# CTRL_MODULE_WKUP_PAD register map
Vendor: Texas Instruments
Peripheral module from a debugger description file (folder omap5430_ES2_PUBLIC).
Registers are 32-bit, access per field, reset 0x0 unless marked. A register's access mark holds for its fields unless they carry their own. Offsets are as the file gives them; lines under a group give offsets from that group; [hi:lo] are bit positions; {n}, {i} and the like mark numbered series; 'fields as' and 'values as' point back to an identical list; <NAME> marks a mode.

## CTRL_MODULE_WKUP_PAD
0x00 CONTROL_WKUP_PAD_REVISION ro reset not defined — Control module revision identifier Access conditions. Read: unrestricted, Write: unrestricted
  [31:0] REVISON — IP Revision enum=hl_scheme . enum=legacy_scheme .
0x04 CONTROL_WKUP_PAD_HWINFO ro — Information about the IP module hardware configuration i.e. typically the module HDL generics (if any). Access conditions. Read: unrestricted, Write: unrestricted
  [31:0] IP_HWINFO — IP-module dependent
0x10 CONTROL_WKUP_PAD_SYSCONFIG reset 0x8 — Access conditions. Read: unrestricted, Write: unrestricted
  [3:2] IP_SYSCONFIG_IDLEMODE rw — RESERVED (not used).
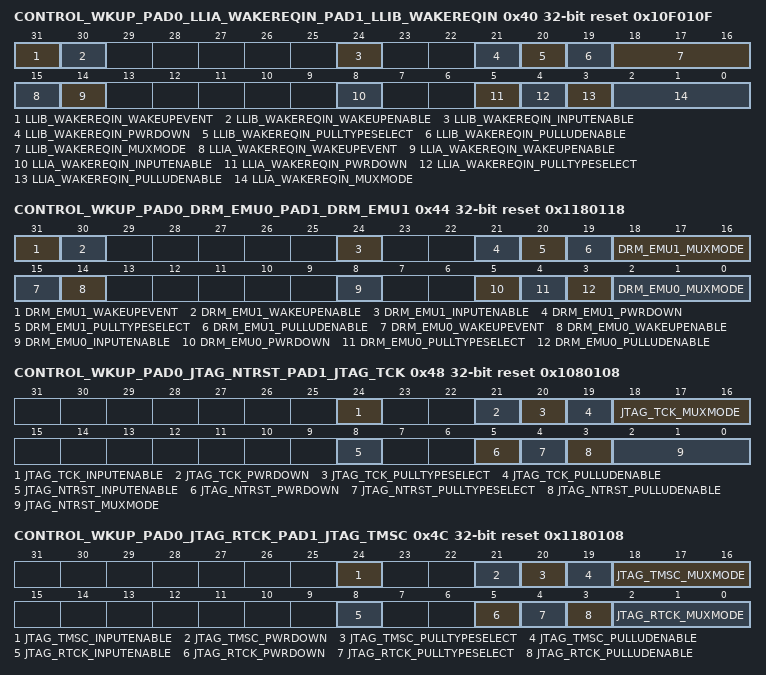
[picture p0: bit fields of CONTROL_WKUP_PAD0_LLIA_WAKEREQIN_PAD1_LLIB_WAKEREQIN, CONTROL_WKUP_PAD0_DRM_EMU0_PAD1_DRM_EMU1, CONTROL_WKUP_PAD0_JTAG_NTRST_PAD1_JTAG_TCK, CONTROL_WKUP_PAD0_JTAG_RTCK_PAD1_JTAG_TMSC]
0x40 CONTROL_WKUP_PAD0_LLIA_WAKEREQIN_PAD1_LLIB_WAKEREQIN reset 0x10F010F — Register control for Pads llia_wakereqin and llib_wakereqin Access conditions. Read: unrestricted, Write: unrestricted
  [31] LLIB_WAKEREQIN_WAKEUPEVENT ro — Pad_x wake-up event status latched in the IO
    1=WakeUp (A wake-up event occurred); 0=No wake-up event occurred
  [30] LLIB_WAKEREQIN_WAKEUPENABLE rw — Input pad wake-up enable
    0=DetectLow (wake-up detection is disabled); 1=DetectLowHigh (wake-up detection is enabled)
  [24] LLIB_WAKEREQIN_INPUTENABLE rw — Input enable value for pad llib_wakereqin
    0=InputBufferDisabled (Input buffer of IO cell is disabled); 1=InputBufferEnabled (Input buffer of IO cell is enabled)
  [21] LLIB_WAKEREQIN_PWRDOWN rw — Power Down setting for pad llib_wakereqin
    0=PwrDownDisabled (IO cell power is ON); 1=PwrDownEnabled (IO cell power is OFF)
  [20] LLIB_WAKEREQIN_PULLTYPESELECT rw — Pull-Up/Down selection for pad llib_wakereqin
    0=Pull-Down selected; 1=Pull-Up selected
  [19] LLIB_WAKEREQIN_PULLUDENABLE rw — Pull-Up/Down enable for pad llib_wakereqin
    0=PullDisabled (Pull-Up/Down disabled); 1=PullEnabled (Pull-Up/Down enabled)
  [18:16] LLIB_WAKEREQIN_MUXMODE rw — Functional multiplexing selection for pad llib_wakereqin
    0=SEL_LLIB_WAKEREQIN (Select llib_wakereqin); 1=SEL_SYS_C2C_PWKUP (Reserved); 6=SEL_GPIO1_WK15 (Select gpio1_wk15); 7=SEL_SAFE_MODE_WAKEUP0 (Select safe_mode_wakeup0); 5=SEL_HW_WKDBG13 (Select hw_wkdbg13)
  [15] LLIA_WAKEREQIN_WAKEUPEVENT ro — Pad_x wake-up event status latched in the IO
    values as LLIB_WAKEREQIN_WAKEUPEVENT
  [14] LLIA_WAKEREQIN_WAKEUPENABLE rw — Input pad wake-up enable
    values as LLIB_WAKEREQIN_WAKEUPENABLE
  [8] LLIA_WAKEREQIN_INPUTENABLE rw — Input enable value for pad llia_wakereqin
    values as LLIB_WAKEREQIN_INPUTENABLE
  [5] LLIA_WAKEREQIN_PWRDOWN rw — Power Down setting for pad llia_wakereqin
    values as LLIB_WAKEREQIN_PWRDOWN
  [4] LLIA_WAKEREQIN_PULLTYPESELECT rw — Pull-Up/Down selection for pad llia_wakereqin
    0=Pull-Down selected; 1=Pull-Up selected
  [3] LLIA_WAKEREQIN_PULLUDENABLE rw — Pull-Up/Down enable for pad llia_wakereqin
    values as LLIB_WAKEREQIN_PULLUDENABLE
  [2:0] LLIA_WAKEREQIN_MUXMODE rw — Functional multiplexing selection for pad llia_wakereqin
    0=SEL_LLIA_WAKEREQIN (Select llia_wakereqin); 1=SEL_C2C_WAKEREQIN (Reserved); 6=SEL_GPIO1_WK14 (Select gpio1_wk14); 7=SEL_SAFE_MODE_WAKEUP1 (Select safe_mode_wakeup1); 5=SEL_HW_WKDBG14 (Select hw_wkdbg14)
0x44 CONTROL_WKUP_PAD0_DRM_EMU0_PAD1_DRM_EMU1 reset 0x1180118 — Register control for Pads drm_emu0 and drm_emu1 Access conditions. Read: unrestricted, Write: unrestricted
  [31] DRM_EMU1_WAKEUPEVENT ro — Pad_x wake-up event status latched in the IO
    values as CONTROL_WKUP_PAD0_LLIA_WAKEREQIN_PAD1_LLIB_WAKEREQIN.LLIB_WAKEREQIN_WAKEUPEVENT
  [30] DRM_EMU1_WAKEUPENABLE rw — Input pad wake-up enable
    values as CONTROL_WKUP_PAD0_LLIA_WAKEREQIN_PAD1_LLIB_WAKEREQIN.LLIB_WAKEREQIN_WAKEUPENABLE
  [24] DRM_EMU1_INPUTENABLE rw — Input enable value for pad drm_emu1
    values as CONTROL_WKUP_PAD0_LLIA_WAKEREQIN_PAD1_LLIB_WAKEREQIN.LLIB_WAKEREQIN_INPUTENABLE
  [21] DRM_EMU1_PWRDOWN rw — Power Down setting for pad drm_emu1
    values as CONTROL_WKUP_PAD0_LLIA_WAKEREQIN_PAD1_LLIB_WAKEREQIN.LLIB_WAKEREQIN_PWRDOWN
  [20] DRM_EMU1_PULLTYPESELECT rw — Pull-Up/Down selection for pad drm_emu1
    0=Pull-Down selected; 1=Pull-Up selected
  [19] DRM_EMU1_PULLUDENABLE rw — Pull-Up/Down enable for pad drm_emu1
    values as CONTROL_WKUP_PAD0_LLIA_WAKEREQIN_PAD1_LLIB_WAKEREQIN.LLIB_WAKEREQIN_PULLUDENABLE
  [18:16] DRM_EMU1_MUXMODE rw — Functional multiplexing selection for pad drm_emu1
    0=SEL_DRM_EMU1 (Select drm_emu1); 6=SEL_GPIO1_WK7 (Select gpio1_wk7); 7=SEL_SAFE_MODE_WAKEUP3 (Select safe_mode_wakeup3); 5=SEL_HW_WKDBG7 (Select hw_wkdbg7)
  [15] DRM_EMU0_WAKEUPEVENT ro — Pad_x wake-up event status latched in the IO
    values as CONTROL_WKUP_PAD0_LLIA_WAKEREQIN_PAD1_LLIB_WAKEREQIN.LLIB_WAKEREQIN_WAKEUPEVENT
  [14] DRM_EMU0_WAKEUPENABLE rw — Input pad wake-up enable
    values as CONTROL_WKUP_PAD0_LLIA_WAKEREQIN_PAD1_LLIB_WAKEREQIN.LLIB_WAKEREQIN_WAKEUPENABLE
  [8] DRM_EMU0_INPUTENABLE rw — Input enable value for pad drm_emu0
    values as CONTROL_WKUP_PAD0_LLIA_WAKEREQIN_PAD1_LLIB_WAKEREQIN.LLIB_WAKEREQIN_INPUTENABLE
  [5] DRM_EMU0_PWRDOWN rw — Power Down setting for pad drm_emu0
    values as CONTROL_WKUP_PAD0_LLIA_WAKEREQIN_PAD1_LLIB_WAKEREQIN.LLIB_WAKEREQIN_PWRDOWN
  [4] DRM_EMU0_PULLTYPESELECT rw — Pull-Up/Down selection for pad drm_emu0
    0=Pull-Down selected; 1=Pull-Up selected
  [3] DRM_EMU0_PULLUDENABLE rw — Pull-Up/Down enable for pad drm_emu0
    values as CONTROL_WKUP_PAD0_LLIA_WAKEREQIN_PAD1_LLIB_WAKEREQIN.LLIB_WAKEREQIN_PULLUDENABLE
  [2:0] DRM_EMU0_MUXMODE rw — Functional multiplexing selection for pad drm_emu0
    0=SEL_DRM_EMU0 (Select drm_emu0); 6=SEL_GPIO1_WK6 (Select gpio1_wk6); 7=SEL_SAFE_MODE_WAKEUP2 (Select safe_mode_wakeup2); 5=SEL_HW_WKDBG6 (Select hw_wkdbg6)
0x48 CONTROL_WKUP_PAD0_JTAG_NTRST_PAD1_JTAG_TCK reset 0x1080108 — Register control for Pads jtag_ntrst and jtag_tck Access conditions. Read: unrestricted, Write: unrestricted
  [24] JTAG_TCK_INPUTENABLE rw — Input enable value for pad jtag_tck
    values as CONTROL_WKUP_PAD0_LLIA_WAKEREQIN_PAD1_LLIB_WAKEREQIN.LLIB_WAKEREQIN_INPUTENABLE
  [21] JTAG_TCK_PWRDOWN rw — Power Down setting for pad jtag_tck
    values as CONTROL_WKUP_PAD0_LLIA_WAKEREQIN_PAD1_LLIB_WAKEREQIN.LLIB_WAKEREQIN_PWRDOWN
  [20] JTAG_TCK_PULLTYPESELECT rw — Pull-Up/Down selection for pad jtag_tck
    0=Pull-Down selected; 1=Pull-Up selected
  [19] JTAG_TCK_PULLUDENABLE rw — Pull-Up/Down enable for pad jtag_tck
    values as CONTROL_WKUP_PAD0_LLIA_WAKEREQIN_PAD1_LLIB_WAKEREQIN.LLIB_WAKEREQIN_PULLUDENABLE
  [18:16] JTAG_TCK_MUXMODE rw — Functional multiplexing selection for pad jtag_tck
    0=SEL_JTAG_TCK (Select jtag_tck); 7=SEL_SAFE_MODE_WAKEUP5 (Select safe_mode_wakeup5)
  [8] JTAG_NTRST_INPUTENABLE rw — Input enable value for pad jtag_ntrst
    values as CONTROL_WKUP_PAD0_LLIA_WAKEREQIN_PAD1_LLIB_WAKEREQIN.LLIB_WAKEREQIN_INPUTENABLE
  [5] JTAG_NTRST_PWRDOWN rw — Power Down setting for pad jtag_ntrst
    values as CONTROL_WKUP_PAD0_LLIA_WAKEREQIN_PAD1_LLIB_WAKEREQIN.LLIB_WAKEREQIN_PWRDOWN
  [4] JTAG_NTRST_PULLTYPESELECT rw — Pull-Up/Down selection for pad jtag_ntrst
    0=Pull-Down selected; 1=Pull-Up selected
  [3] JTAG_NTRST_PULLUDENABLE rw — Pull-Up/Down enable for pad jtag_ntrst
    values as CONTROL_WKUP_PAD0_LLIA_WAKEREQIN_PAD1_LLIB_WAKEREQIN.LLIB_WAKEREQIN_PULLUDENABLE
  [2:0] JTAG_NTRST_MUXMODE rw — Functional multiplexing selection for pad jtag_ntrst
    0=SEL_JTAG_NTRST (Select jtag_ntrst); 7=SEL_SAFE_MODE_WAKEUP4 (Select safe_mode_wakeup4)
0x4C CONTROL_WKUP_PAD0_JTAG_RTCK_PAD1_JTAG_TMSC reset 0x1180108 — Register control for Pads jtag_rtck and jtag_tmsc Access conditions. Read: unrestricted, Write: unrestricted
  [24] JTAG_TMSC_INPUTENABLE rw — Input enable value for pad jtag_tmsc
    values as CONTROL_WKUP_PAD0_LLIA_WAKEREQIN_PAD1_LLIB_WAKEREQIN.LLIB_WAKEREQIN_INPUTENABLE
  [21] JTAG_TMSC_PWRDOWN rw — Power Down setting for pad jtag_tmsc
    values as CONTROL_WKUP_PAD0_LLIA_WAKEREQIN_PAD1_LLIB_WAKEREQIN.LLIB_WAKEREQIN_PWRDOWN
  [20] JTAG_TMSC_PULLTYPESELECT rw — Pull-Up/Down selection for pad jtag_tmsc
    0=Pull-Down selected; 1=Pull-Up selected
  [19] JTAG_TMSC_PULLUDENABLE rw — Pull-Up/Down enable for pad jtag_tmsc
    values as CONTROL_WKUP_PAD0_LLIA_WAKEREQIN_PAD1_LLIB_WAKEREQIN.LLIB_WAKEREQIN_PULLUDENABLE
  [18:16] JTAG_TMSC_MUXMODE rw — Functional multiplexing selection for pad jtag_tmsc
    0=SEL_JTAG_TMSC (Select jtag_tmsc); 7=SEL_SAFE_MODE_WAKEUP7 (Select safe_mode_wakeup7)
  [8] JTAG_RTCK_INPUTENABLE rw — Input enable value for pad jtag_rtck
    values as CONTROL_WKUP_PAD0_LLIA_WAKEREQIN_PAD1_LLIB_WAKEREQIN.LLIB_WAKEREQIN_INPUTENABLE
  [5] JTAG_RTCK_PWRDOWN rw — Power Down setting for pad jtag_rtck
    values as CONTROL_WKUP_PAD0_LLIA_WAKEREQIN_PAD1_LLIB_WAKEREQIN.LLIB_WAKEREQIN_PWRDOWN
  [4] JTAG_RTCK_PULLTYPESELECT rw — Pull-Up/Down selection for pad jtag_rtck
    0=Pull-Down selected; 1=Pull-Up selected
  [3] JTAG_RTCK_PULLUDENABLE rw — Pull-Up/Down enable for pad jtag_rtck
    values as CONTROL_WKUP_PAD0_LLIA_WAKEREQIN_PAD1_LLIB_WAKEREQIN.LLIB_WAKEREQIN_PULLUDENABLE
  [2:0] JTAG_RTCK_MUXMODE rw — Functional multiplexing selection for pad jtag_rtck
    0=SEL_JTAG_RTCK (Select jtag_rtck); 7=SEL_SAFE_MODE_WAKEUP6 (Select safe_mode_wakeup6)
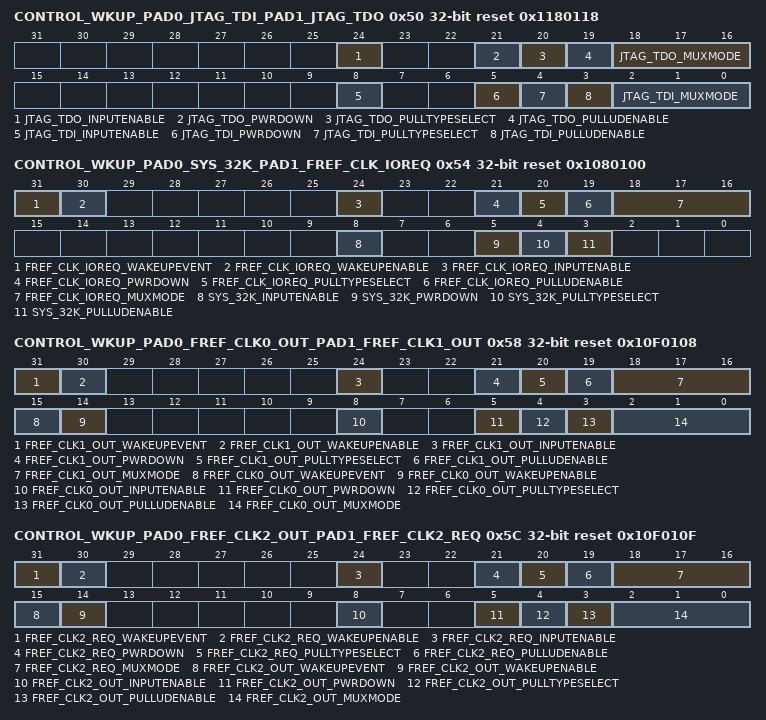
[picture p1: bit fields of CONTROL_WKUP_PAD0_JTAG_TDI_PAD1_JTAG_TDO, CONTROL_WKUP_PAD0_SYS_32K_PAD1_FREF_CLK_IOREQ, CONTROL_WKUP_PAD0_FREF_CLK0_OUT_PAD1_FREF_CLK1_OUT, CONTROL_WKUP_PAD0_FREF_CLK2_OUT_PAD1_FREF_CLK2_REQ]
0x50 CONTROL_WKUP_PAD0_JTAG_TDI_PAD1_JTAG_TDO reset 0x1180118 — Register control for Pads jtag_tdi and jtag_tdo Access conditions. Read: unrestricted, Write: unrestricted
  [24] JTAG_TDO_INPUTENABLE rw — Input enable value for pad jtag_tdo
    values as CONTROL_WKUP_PAD0_LLIA_WAKEREQIN_PAD1_LLIB_WAKEREQIN.LLIB_WAKEREQIN_INPUTENABLE
  [21] JTAG_TDO_PWRDOWN rw — Power Down setting for pad jtag_tdo
    values as CONTROL_WKUP_PAD0_LLIA_WAKEREQIN_PAD1_LLIB_WAKEREQIN.LLIB_WAKEREQIN_PWRDOWN
  [20] JTAG_TDO_PULLTYPESELECT rw — Pull-Up/Down selection for pad jtag_tdo
    0=Pull-Down selected; 1=Pull-Up selected
  [19] JTAG_TDO_PULLUDENABLE rw — Pull-Up/Down enable for pad jtag_tdo
    values as CONTROL_WKUP_PAD0_LLIA_WAKEREQIN_PAD1_LLIB_WAKEREQIN.LLIB_WAKEREQIN_PULLUDENABLE
  [18:16] JTAG_TDO_MUXMODE rw — Functional multiplexing selection for pad jtag_tdo
    0=SEL_JTAG_TDO (Select jtag_tdo); 7=SEL_SAFE_MODE_WAKEUP9 (Select safe_mode_wakeup9)
  [8] JTAG_TDI_INPUTENABLE rw — Input enable value for pad jtag_tdi
    values as CONTROL_WKUP_PAD0_LLIA_WAKEREQIN_PAD1_LLIB_WAKEREQIN.LLIB_WAKEREQIN_INPUTENABLE
  [5] JTAG_TDI_PWRDOWN rw — Power Down setting for pad jtag_tdi
    values as CONTROL_WKUP_PAD0_LLIA_WAKEREQIN_PAD1_LLIB_WAKEREQIN.LLIB_WAKEREQIN_PWRDOWN
  [4] JTAG_TDI_PULLTYPESELECT rw — Pull-Up/Down selection for pad jtag_tdi
    0=Pull-Down selected; 1=Pull-Up selected
  [3] JTAG_TDI_PULLUDENABLE rw — Pull-Up/Down enable for pad jtag_tdi
    values as CONTROL_WKUP_PAD0_LLIA_WAKEREQIN_PAD1_LLIB_WAKEREQIN.LLIB_WAKEREQIN_PULLUDENABLE
  [2:0] JTAG_TDI_MUXMODE rw — Functional multiplexing selection for pad jtag_tdi
    0=SEL_JTAG_TDI (Select jtag_tdi); 7=SEL_SAFE_MODE_WAKEUP8 (Select safe_mode_wakeup8)
0x54 CONTROL_WKUP_PAD0_SYS_32K_PAD1_FREF_CLK_IOREQ reset 0x1080100 — Register control for Pads sys_32k and fref_clk_ioreq Access conditions. Read: unrestricted, Write: unrestricted
  [31] FREF_CLK_IOREQ_WAKEUPEVENT ro — Pad_x wake-up event status latched in the IO
    values as CONTROL_WKUP_PAD0_LLIA_WAKEREQIN_PAD1_LLIB_WAKEREQIN.LLIB_WAKEREQIN_WAKEUPEVENT
  [30] FREF_CLK_IOREQ_WAKEUPENABLE rw — Input pad wake-up enable
    values as CONTROL_WKUP_PAD0_LLIA_WAKEREQIN_PAD1_LLIB_WAKEREQIN.LLIB_WAKEREQIN_WAKEUPENABLE
  [24] FREF_CLK_IOREQ_INPUTENABLE rw — Input enable value for pad fref_clk_ioreq
    values as CONTROL_WKUP_PAD0_LLIA_WAKEREQIN_PAD1_LLIB_WAKEREQIN.LLIB_WAKEREQIN_INPUTENABLE
  [21] FREF_CLK_IOREQ_PWRDOWN rw — Power Down setting for pad fref_clk_ioreq
    values as CONTROL_WKUP_PAD0_LLIA_WAKEREQIN_PAD1_LLIB_WAKEREQIN.LLIB_WAKEREQIN_PWRDOWN
  [20] FREF_CLK_IOREQ_PULLTYPESELECT rw — Pull-Up/Down selection for pad fref_clk_ioreq
    0=Pull-Down selected; 1=Pull-Up selected
  [19] FREF_CLK_IOREQ_PULLUDENABLE rw — Pull-Up/Down enable for pad fref_clk_ioreq
    values as CONTROL_WKUP_PAD0_LLIA_WAKEREQIN_PAD1_LLIB_WAKEREQIN.LLIB_WAKEREQIN_PULLUDENABLE
  [18:16] FREF_CLK_IOREQ_MUXMODE rw — Functional multiplexing selection for pad fref_clk_ioreq
    0=SEL_FREF_CLK_IOREQ (Select fref_clk_ioreq); 7=SEL_SAFE_MODE_WAKEUP10 (Select safe_mode_wakeup10); 6=SEL_GPIO1_WK13 (Select gpio1_wk13)
  [8] SYS_32K_INPUTENABLE rw — Input enable value for pad sys_32k
    values as CONTROL_WKUP_PAD0_LLIA_WAKEREQIN_PAD1_LLIB_WAKEREQIN.LLIB_WAKEREQIN_INPUTENABLE
  [5] SYS_32K_PWRDOWN rw — Power Down setting for pad sys_32k
    values as CONTROL_WKUP_PAD0_LLIA_WAKEREQIN_PAD1_LLIB_WAKEREQIN.LLIB_WAKEREQIN_PWRDOWN
  [4] SYS_32K_PULLTYPESELECT rw — Pull-Up/Down selection for pad sys_32k
    0=Pull-Down selected; 1=Pull-Up selected
  [3] SYS_32K_PULLUDENABLE rw — Pull-Up/Down enable for pad sys_32k
    values as CONTROL_WKUP_PAD0_LLIA_WAKEREQIN_PAD1_LLIB_WAKEREQIN.LLIB_WAKEREQIN_PULLUDENABLE
0x58 CONTROL_WKUP_PAD0_FREF_CLK0_OUT_PAD1_FREF_CLK1_OUT reset 0x10F0108 — Register control for Pads fref_clk0_out and fref_clk1_out Access conditions. Read: unrestricted, Write: unrestricted
  [31] FREF_CLK1_OUT_WAKEUPEVENT ro — Pad_x wake-up event status latched in the IO
    values as CONTROL_WKUP_PAD0_LLIA_WAKEREQIN_PAD1_LLIB_WAKEREQIN.LLIB_WAKEREQIN_WAKEUPEVENT
  [30] FREF_CLK1_OUT_WAKEUPENABLE rw — Input pad wake-up enable
    values as CONTROL_WKUP_PAD0_LLIA_WAKEREQIN_PAD1_LLIB_WAKEREQIN.LLIB_WAKEREQIN_WAKEUPENABLE
  [24] FREF_CLK1_OUT_INPUTENABLE rw — Input enable value for pad fref_clk1_out
    values as CONTROL_WKUP_PAD0_LLIA_WAKEREQIN_PAD1_LLIB_WAKEREQIN.LLIB_WAKEREQIN_INPUTENABLE
  [21] FREF_CLK1_OUT_PWRDOWN rw — Power Down setting for pad fref_clk1_out
    values as CONTROL_WKUP_PAD0_LLIA_WAKEREQIN_PAD1_LLIB_WAKEREQIN.LLIB_WAKEREQIN_PWRDOWN
  [20] FREF_CLK1_OUT_PULLTYPESELECT rw — Pull-Up/Down selection for pad fref_clk1_out
    0=Pull-Down selected; 1=Pull-Up selected
  [19] FREF_CLK1_OUT_PULLUDENABLE rw — Pull-Up/Down enable for pad fref_clk1_out
    values as CONTROL_WKUP_PAD0_LLIA_WAKEREQIN_PAD1_LLIB_WAKEREQIN.LLIB_WAKEREQIN_PULLUDENABLE
  [18:16] FREF_CLK1_OUT_MUXMODE rw — Functional multiplexing selection for pad fref_clk1_out
    0=SEL_FREF_CLK1_OUT (Select fref_clk1_out); 6=SEL_GPIO1_WK11 (Select gpio1_wk11); 7=SEL_SAFE_MODE_WAKEUP12 (Select safe_mode_wakeup12); 5=SEL_HW_WKDBG5 (Select hw_wkdbg5)
  [15] FREF_CLK0_OUT_WAKEUPEVENT ro — Pad_x wake-up event status latched in the IO
    values as CONTROL_WKUP_PAD0_LLIA_WAKEREQIN_PAD1_LLIB_WAKEREQIN.LLIB_WAKEREQIN_WAKEUPEVENT
  [14] FREF_CLK0_OUT_WAKEUPENABLE rw — Input pad wake-up enable
    values as CONTROL_WKUP_PAD0_LLIA_WAKEREQIN_PAD1_LLIB_WAKEREQIN.LLIB_WAKEREQIN_WAKEUPENABLE
  [8] FREF_CLK0_OUT_INPUTENABLE rw — Input enable value for pad fref_clk0_out
    values as CONTROL_WKUP_PAD0_LLIA_WAKEREQIN_PAD1_LLIB_WAKEREQIN.LLIB_WAKEREQIN_INPUTENABLE
  [5] FREF_CLK0_OUT_PWRDOWN rw — Power Down setting for pad fref_clk0_out
    values as CONTROL_WKUP_PAD0_LLIA_WAKEREQIN_PAD1_LLIB_WAKEREQIN.LLIB_WAKEREQIN_PWRDOWN
  [4] FREF_CLK0_OUT_PULLTYPESELECT rw — Pull-Up/Down selection for pad fref_clk0_out
    0=Pull-Down selected; 1=Pull-Up selected
  [3] FREF_CLK0_OUT_PULLUDENABLE rw — Pull-Up/Down enable for pad fref_clk0_out
    values as CONTROL_WKUP_PAD0_LLIA_WAKEREQIN_PAD1_LLIB_WAKEREQIN.LLIB_WAKEREQIN_PULLUDENABLE
  [2:0] FREF_CLK0_OUT_MUXMODE rw — Functional multiplexing selection for pad fref_clk0_out
    0=SEL_FREF_CLK0_OUT (Select fref_clk0_out); 6=SEL_GPIO1_WK12 (Select gpio1_wk12); 7=SEL_SAFE_MODE_WAKEUP11 (Select safe_mode_wakeup11); 5=SEL_HW_WKDBG9 (Select hw_wkdbg9)
0x5C CONTROL_WKUP_PAD0_FREF_CLK2_OUT_PAD1_FREF_CLK2_REQ reset 0x10F010F — Register control for Pads fref_clk2_out and fref_clk2_req Access conditions. Read: unrestricted, Write: unrestricted
  [31] FREF_CLK2_REQ_WAKEUPEVENT ro — Pad_x wake-up event status latched in the IO
    values as CONTROL_WKUP_PAD0_LLIA_WAKEREQIN_PAD1_LLIB_WAKEREQIN.LLIB_WAKEREQIN_WAKEUPEVENT
  [30] FREF_CLK2_REQ_WAKEUPENABLE rw — Input pad wake-up enable
    values as CONTROL_WKUP_PAD0_LLIA_WAKEREQIN_PAD1_LLIB_WAKEREQIN.LLIB_WAKEREQIN_WAKEUPENABLE
  [24] FREF_CLK2_REQ_INPUTENABLE rw — Input enable value for pad fref_clk2_req
    values as CONTROL_WKUP_PAD0_LLIA_WAKEREQIN_PAD1_LLIB_WAKEREQIN.LLIB_WAKEREQIN_INPUTENABLE
  [21] FREF_CLK2_REQ_PWRDOWN rw — Power Down setting for pad fref_clk2_req
    values as CONTROL_WKUP_PAD0_LLIA_WAKEREQIN_PAD1_LLIB_WAKEREQIN.LLIB_WAKEREQIN_PWRDOWN
  [20] FREF_CLK2_REQ_PULLTYPESELECT rw — Pull-Up/Down selection for pad fref_clk2_req
    0=Pull-Down selected; 1=Pull-Up selected
  [19] FREF_CLK2_REQ_PULLUDENABLE rw — Pull-Up/Down enable for pad fref_clk2_req
    values as CONTROL_WKUP_PAD0_LLIA_WAKEREQIN_PAD1_LLIB_WAKEREQIN.LLIB_WAKEREQIN_PULLUDENABLE
  [18:16] FREF_CLK2_REQ_MUXMODE rw — Functional multiplexing selection for pad fref_clk2_req
    6=SEL_GPIO1_WK9 (Select gpio1_wk9); 1=SEL_FREF_CLK3_OUT (Select fref_clk3_out); 7=SEL_SAFE_MODE_WAKEUP14 (Select safe_mode_wakeup14); 0=SEL_FREF_CLK2_REQ (Select fref_clk2_req); 5=SEL_HW_WKDBG11 (Select hw_wkdbg11); 3=SEL_SYS_NDMAREQ0 (Select sys_ndmareq0)
  [15] FREF_CLK2_OUT_WAKEUPEVENT ro — Pad_x wake-up event status latched in the IO
    values as CONTROL_WKUP_PAD0_LLIA_WAKEREQIN_PAD1_LLIB_WAKEREQIN.LLIB_WAKEREQIN_WAKEUPEVENT
  [14] FREF_CLK2_OUT_WAKEUPENABLE rw — Input pad wake-up enable
    values as CONTROL_WKUP_PAD0_LLIA_WAKEREQIN_PAD1_LLIB_WAKEREQIN.LLIB_WAKEREQIN_WAKEUPENABLE
  [8] FREF_CLK2_OUT_INPUTENABLE rw — Input enable value for pad fref_clk2_out
    values as CONTROL_WKUP_PAD0_LLIA_WAKEREQIN_PAD1_LLIB_WAKEREQIN.LLIB_WAKEREQIN_INPUTENABLE
  [5] FREF_CLK2_OUT_PWRDOWN rw — Power Down setting for pad fref_clk2_out
    values as CONTROL_WKUP_PAD0_LLIA_WAKEREQIN_PAD1_LLIB_WAKEREQIN.LLIB_WAKEREQIN_PWRDOWN
  [4] FREF_CLK2_OUT_PULLTYPESELECT rw — Pull-Up/Down selection for pad fref_clk2_out
    0=Pull-Down selected; 1=Pull-Up selected
  [3] FREF_CLK2_OUT_PULLUDENABLE rw — Pull-Up/Down enable for pad fref_clk2_out
    values as CONTROL_WKUP_PAD0_LLIA_WAKEREQIN_PAD1_LLIB_WAKEREQIN.LLIB_WAKEREQIN_PULLUDENABLE
  [2:0] FREF_CLK2_OUT_MUXMODE rw — Functional multiplexing selection for pad fref_clk2_out
    0=SEL_FREF_CLK2_OUT (Select fref_clk2_out); 6=SEL_GPIO1_WK10 (Select gpio1_wk10); 7=SEL_SAFE_MODE_WAKEUP13 (Select safe_mode_wakeup13); 5=SEL_HW_WKDBG10 (Select hw_wkdbg10)
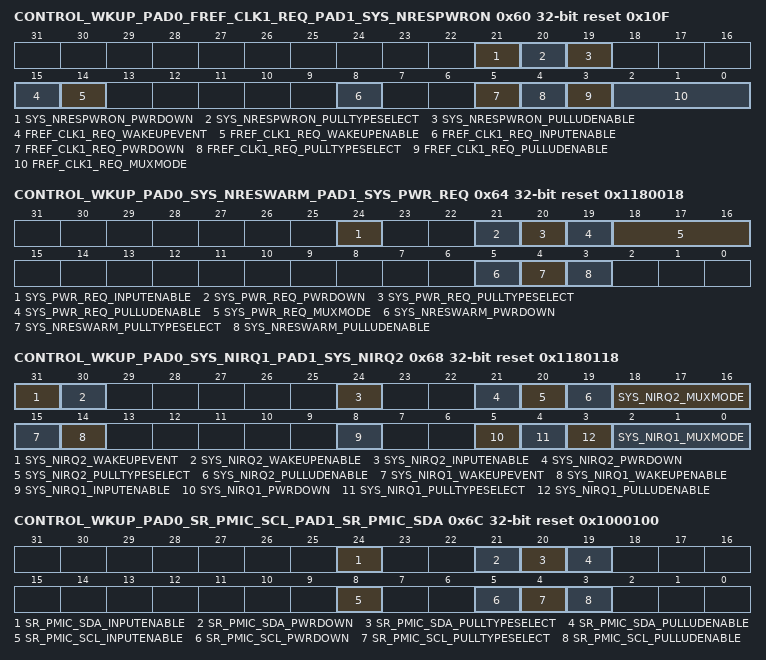
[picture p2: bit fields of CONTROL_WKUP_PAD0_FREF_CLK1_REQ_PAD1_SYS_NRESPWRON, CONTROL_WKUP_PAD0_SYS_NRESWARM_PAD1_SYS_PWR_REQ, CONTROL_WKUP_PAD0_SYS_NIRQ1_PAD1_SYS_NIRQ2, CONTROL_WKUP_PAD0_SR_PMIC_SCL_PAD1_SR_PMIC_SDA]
0x60 CONTROL_WKUP_PAD0_FREF_CLK1_REQ_PAD1_SYS_NRESPWRON reset 0x10F — Register control for Pads fref_clk1_req and sys_nrespwron Access conditions. Read: unrestricted, Write: unrestricted
  [21] SYS_NRESPWRON_PWRDOWN rw — Power Down setting for pad sys_nrespwron
    values as CONTROL_WKUP_PAD0_LLIA_WAKEREQIN_PAD1_LLIB_WAKEREQIN.LLIB_WAKEREQIN_PWRDOWN
  [20] SYS_NRESPWRON_PULLTYPESELECT rw — Pull-Up/Down selection for pad sys_nrespwron
    0=Pull-Down selected; 1=Pull-Up selected
  [19] SYS_NRESPWRON_PULLUDENABLE rw — Pull-Up/Down enable for pad sys_nrespwron
    values as CONTROL_WKUP_PAD0_LLIA_WAKEREQIN_PAD1_LLIB_WAKEREQIN.LLIB_WAKEREQIN_PULLUDENABLE
  [15] FREF_CLK1_REQ_WAKEUPEVENT ro — Pad_x wake-up event status latched in the IO
    values as CONTROL_WKUP_PAD0_LLIA_WAKEREQIN_PAD1_LLIB_WAKEREQIN.LLIB_WAKEREQIN_WAKEUPEVENT
  [14] FREF_CLK1_REQ_WAKEUPENABLE rw — Input pad wake-up enable
    values as CONTROL_WKUP_PAD0_LLIA_WAKEREQIN_PAD1_LLIB_WAKEREQIN.LLIB_WAKEREQIN_WAKEUPENABLE
  [8] FREF_CLK1_REQ_INPUTENABLE rw — Input enable value for pad fref_clk1_req
    values as CONTROL_WKUP_PAD0_LLIA_WAKEREQIN_PAD1_LLIB_WAKEREQIN.LLIB_WAKEREQIN_INPUTENABLE
  [5] FREF_CLK1_REQ_PWRDOWN rw — Power Down setting for pad fref_clk1_req
    values as CONTROL_WKUP_PAD0_LLIA_WAKEREQIN_PAD1_LLIB_WAKEREQIN.LLIB_WAKEREQIN_PWRDOWN
  [4] FREF_CLK1_REQ_PULLTYPESELECT rw — Pull-Up/Down selection for pad fref_clk1_req
    0=Pull-Down selected; 1=Pull-Up selected
  [3] FREF_CLK1_REQ_PULLUDENABLE rw — Pull-Up/Down enable for pad fref_clk1_req
    values as CONTROL_WKUP_PAD0_LLIA_WAKEREQIN_PAD1_LLIB_WAKEREQIN.LLIB_WAKEREQIN_PULLUDENABLE
  [2:0] FREF_CLK1_REQ_MUXMODE rw — Functional multiplexing selection for pad fref_clk1_req
    0=SEL_FREF_CLK1_REQ (Select fref_clk1_req); 6=SEL_GPIO1_WK8 (Select gpio1_wk8); 3=SEL_SYS_NDMAREQ1 (Select sys_ndmareq1); 7=SEL_SAFE_MODE_WAKEUP15 (Select safe_mode_wakeup15); 5=SEL_HW_WKDBG12 (Select hw_wkdbg12)
0x64 CONTROL_WKUP_PAD0_SYS_NRESWARM_PAD1_SYS_PWR_REQ reset 0x1180018 — Register control for Pads sys_nreswarm and sys_pwr_req Access conditions. Read: unrestricted, Write: unrestricted
  [24] SYS_PWR_REQ_INPUTENABLE rw — Input enable value for pad sys_pwr_req
    values as CONTROL_WKUP_PAD0_LLIA_WAKEREQIN_PAD1_LLIB_WAKEREQIN.LLIB_WAKEREQIN_INPUTENABLE
  [21] SYS_PWR_REQ_PWRDOWN rw — Power Down setting for pad sys_pwr_req
    values as CONTROL_WKUP_PAD0_LLIA_WAKEREQIN_PAD1_LLIB_WAKEREQIN.LLIB_WAKEREQIN_PWRDOWN
  [20] SYS_PWR_REQ_PULLTYPESELECT rw — Pull-Up/Down selection for pad sys_pwr_req
    0=Pull-Down selected; 1=Pull-Up selected
  [19] SYS_PWR_REQ_PULLUDENABLE rw — Pull-Up/Down enable for pad sys_pwr_req
    values as CONTROL_WKUP_PAD0_LLIA_WAKEREQIN_PAD1_LLIB_WAKEREQIN.LLIB_WAKEREQIN_PULLUDENABLE
  [18:16] SYS_PWR_REQ_MUXMODE rw — Functional multiplexing selection for pad sys_pwr_req
    0=SEL_SYS_PWR_REQ (Select sys_pwr_req); 7=SEL_SAFE_MODE_WAKEUP16 (Select safe_mode_wakeup16); 5=SEL_HW_WKDBG15 (Select hw_wkdbg15)
  [5] SYS_NRESWARM_PWRDOWN rw — Power Down setting for pad sys_nreswarm
    values as CONTROL_WKUP_PAD0_LLIA_WAKEREQIN_PAD1_LLIB_WAKEREQIN.LLIB_WAKEREQIN_PWRDOWN
  [4] SYS_NRESWARM_PULLTYPESELECT rw — Pull-Up/Down selection for pad sys_nreswarm
    0=Pull-Down selected; 1=Pull-Up selected
  [3] SYS_NRESWARM_PULLUDENABLE rw — Pull-Up/Down enable for pad sys_nreswarm
    values as CONTROL_WKUP_PAD0_LLIA_WAKEREQIN_PAD1_LLIB_WAKEREQIN.LLIB_WAKEREQIN_PULLUDENABLE
0x68 CONTROL_WKUP_PAD0_SYS_NIRQ1_PAD1_SYS_NIRQ2 reset 0x1180118 — Register control for Pads sys_nirq1 and sys_nirq2 Access conditions. Read: unrestricted, Write: unrestricted
  [31] SYS_NIRQ2_WAKEUPEVENT ro — Pad_x wake-up event status latched in the IO
    values as CONTROL_WKUP_PAD0_LLIA_WAKEREQIN_PAD1_LLIB_WAKEREQIN.LLIB_WAKEREQIN_WAKEUPEVENT
  [30] SYS_NIRQ2_WAKEUPENABLE rw — Input pad wake-up enable
    values as CONTROL_WKUP_PAD0_LLIA_WAKEREQIN_PAD1_LLIB_WAKEREQIN.LLIB_WAKEREQIN_WAKEUPENABLE
  [24] SYS_NIRQ2_INPUTENABLE rw — Input enable value for pad sys_nirq2
    values as CONTROL_WKUP_PAD0_LLIA_WAKEREQIN_PAD1_LLIB_WAKEREQIN.LLIB_WAKEREQIN_INPUTENABLE
  [21] SYS_NIRQ2_PWRDOWN rw — Power Down setting for pad sys_nirq2
    values as CONTROL_WKUP_PAD0_LLIA_WAKEREQIN_PAD1_LLIB_WAKEREQIN.LLIB_WAKEREQIN_PWRDOWN
  [20] SYS_NIRQ2_PULLTYPESELECT rw — Pull-Up/Down selection for pad sys_nirq2
    0=Pull-Down selected; 1=Pull-Up selected
  [19] SYS_NIRQ2_PULLUDENABLE rw — Pull-Up/Down enable for pad sys_nirq2
    values as CONTROL_WKUP_PAD0_LLIA_WAKEREQIN_PAD1_LLIB_WAKEREQIN.LLIB_WAKEREQIN_PULLUDENABLE
  [18:16] SYS_NIRQ2_MUXMODE rw — Functional multiplexing selection for pad sys_nirq2
    0=SEL_SYS_NIRQ2 (Select sys_nirq2); 6=SEL_GPIO1_WK17 (Select gpio1_wk17)
  [15] SYS_NIRQ1_WAKEUPEVENT ro — Pad_x wake-up event status latched in the IO
    values as CONTROL_WKUP_PAD0_LLIA_WAKEREQIN_PAD1_LLIB_WAKEREQIN.LLIB_WAKEREQIN_WAKEUPEVENT
  [14] SYS_NIRQ1_WAKEUPENABLE rw — Input pad wake-up enable
    values as CONTROL_WKUP_PAD0_LLIA_WAKEREQIN_PAD1_LLIB_WAKEREQIN.LLIB_WAKEREQIN_WAKEUPENABLE
  [8] SYS_NIRQ1_INPUTENABLE rw — Input enable value for pad sys_nirq1
    values as CONTROL_WKUP_PAD0_LLIA_WAKEREQIN_PAD1_LLIB_WAKEREQIN.LLIB_WAKEREQIN_INPUTENABLE
  [5] SYS_NIRQ1_PWRDOWN rw — Power Down setting for pad sys_nirq1
    values as CONTROL_WKUP_PAD0_LLIA_WAKEREQIN_PAD1_LLIB_WAKEREQIN.LLIB_WAKEREQIN_PWRDOWN
  [4] SYS_NIRQ1_PULLTYPESELECT rw — Pull-Up/Down selection for pad sys_nirq1
    0=Pull-Down selected; 1=Pull-Up selected
  [3] SYS_NIRQ1_PULLUDENABLE rw — Pull-Up/Down enable for pad sys_nirq1
    values as CONTROL_WKUP_PAD0_LLIA_WAKEREQIN_PAD1_LLIB_WAKEREQIN.LLIB_WAKEREQIN_PULLUDENABLE
  [2:0] SYS_NIRQ1_MUXMODE rw — Functional multiplexing selection for pad sys_nirq1
    0=SEL_SYS_NIRQ1 (Select sys_nirq1); 6=SEL_GPIO1_WK16 (Select gpio1_wk16)
0x6C CONTROL_WKUP_PAD0_SR_PMIC_SCL_PAD1_SR_PMIC_SDA reset 0x1000100 — Register control for Pads sr_pmic_scl and sr_pmic_sda Access conditions. Read: unrestricted, Write: unrestricted
  [24] SR_PMIC_SDA_INPUTENABLE rw — Input enable value for pad sr_pmic_sda
    values as CONTROL_WKUP_PAD0_LLIA_WAKEREQIN_PAD1_LLIB_WAKEREQIN.LLIB_WAKEREQIN_INPUTENABLE
  [21] SR_PMIC_SDA_PWRDOWN rw — Power Down setting for pad sr_pmic_sda
    values as CONTROL_WKUP_PAD0_LLIA_WAKEREQIN_PAD1_LLIB_WAKEREQIN.LLIB_WAKEREQIN_PWRDOWN
  [20] SR_PMIC_SDA_PULLTYPESELECT rw — Pull-Up/Down selection for pad sr_pmic_sda
    0=Pull-Down selected; 1=Pull-Up selected
  [19] SR_PMIC_SDA_PULLUDENABLE rw — Pull-Up/Down enable for pad sr_pmic_sda
    values as CONTROL_WKUP_PAD0_LLIA_WAKEREQIN_PAD1_LLIB_WAKEREQIN.LLIB_WAKEREQIN_PULLUDENABLE
  [8] SR_PMIC_SCL_INPUTENABLE rw — Input enable value for pad sr_pmic_scl
    values as CONTROL_WKUP_PAD0_LLIA_WAKEREQIN_PAD1_LLIB_WAKEREQIN.LLIB_WAKEREQIN_INPUTENABLE
  [5] SR_PMIC_SCL_PWRDOWN rw — Power Down setting for pad sr_pmic_scl
    values as CONTROL_WKUP_PAD0_LLIA_WAKEREQIN_PAD1_LLIB_WAKEREQIN.LLIB_WAKEREQIN_PWRDOWN
  [4] SR_PMIC_SCL_PULLTYPESELECT rw — Pull-Up/Down selection for pad sr_pmic_scl
    0=Pull-Down selected; 1=Pull-Up selected
  [3] SR_PMIC_SCL_PULLUDENABLE rw — Pull-Up/Down enable for pad sr_pmic_scl
    values as CONTROL_WKUP_PAD0_LLIA_WAKEREQIN_PAD1_LLIB_WAKEREQIN.LLIB_WAKEREQIN_PULLUDENABLE
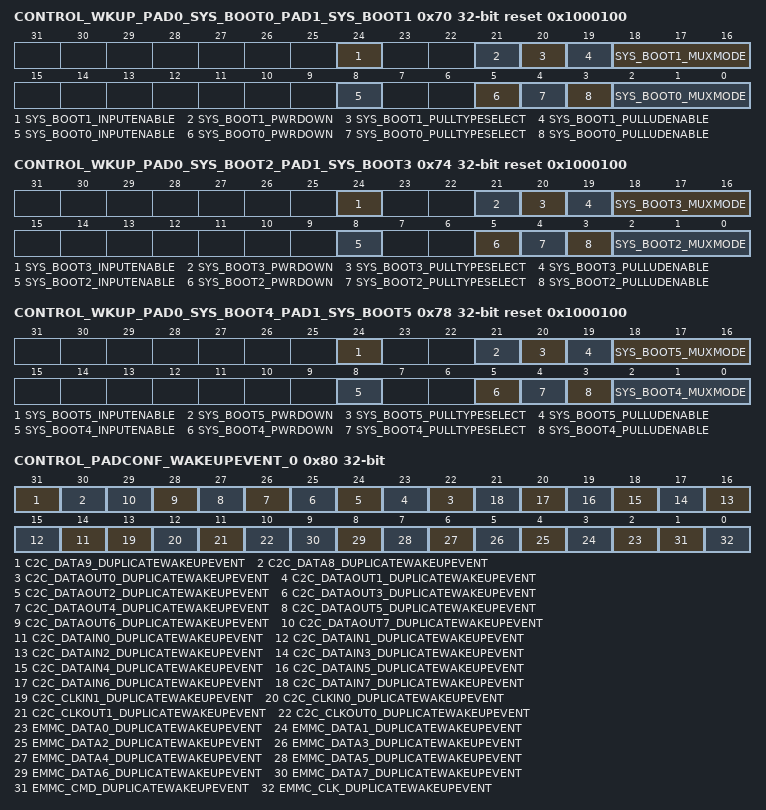
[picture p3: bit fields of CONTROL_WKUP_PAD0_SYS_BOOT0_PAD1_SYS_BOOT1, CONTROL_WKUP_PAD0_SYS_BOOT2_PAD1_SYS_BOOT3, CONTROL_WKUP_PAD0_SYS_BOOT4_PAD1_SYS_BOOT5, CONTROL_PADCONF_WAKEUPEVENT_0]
0x70 CONTROL_WKUP_PAD0_SYS_BOOT0_PAD1_SYS_BOOT1 reset 0x1000100 — Register control for Pads sys_boot0 and sys_boot1 Access conditions. Read: unrestricted, Write: unrestricted
  [24] SYS_BOOT1_INPUTENABLE rw — Input enable value for pad sys_boot1
    values as CONTROL_WKUP_PAD0_LLIA_WAKEREQIN_PAD1_LLIB_WAKEREQIN.LLIB_WAKEREQIN_INPUTENABLE
  [21] SYS_BOOT1_PWRDOWN rw — Power Down setting for pad sys_boot1
    values as CONTROL_WKUP_PAD0_LLIA_WAKEREQIN_PAD1_LLIB_WAKEREQIN.LLIB_WAKEREQIN_PWRDOWN
  [20] SYS_BOOT1_PULLTYPESELECT rw — Pull-Up/Down selection for pad sys_boot1
    0=Pull-Down selected; 1=Pull-Up selected
  [19] SYS_BOOT1_PULLUDENABLE rw — Pull-Up/Down enable for pad sys_boot1
    values as CONTROL_WKUP_PAD0_LLIA_WAKEREQIN_PAD1_LLIB_WAKEREQIN.LLIB_WAKEREQIN_PULLUDENABLE
  [18:16] SYS_BOOT1_MUXMODE rw — Functional multiplexing selection for pad sys_boot1
    6=SEL_GPIO1_WKOUT1 (Select gpio1_wkout1); 7=SEL_SAFE_MODE_WAKEUP18 (Select safe_mode_wakeup18); 0=SEL_SYS_BOOT1 (Select sys_boot1); 4=SEL_DRM_EMU16 (Select drm_emu16); 5=SEL_HW_WKDBG1 (Select hw_wkdbg1); 3=SEL_DRM_EMU3 (Select drm_emu3)
  [8] SYS_BOOT0_INPUTENABLE rw — Input enable value for pad sys_boot0
    values as CONTROL_WKUP_PAD0_LLIA_WAKEREQIN_PAD1_LLIB_WAKEREQIN.LLIB_WAKEREQIN_INPUTENABLE
  [5] SYS_BOOT0_PWRDOWN rw — Power Down setting for pad sys_boot0
    values as CONTROL_WKUP_PAD0_LLIA_WAKEREQIN_PAD1_LLIB_WAKEREQIN.LLIB_WAKEREQIN_PWRDOWN
  [4] SYS_BOOT0_PULLTYPESELECT rw — Pull-Up/Down selection for pad sys_boot0
    0=Pull-Down selected; 1=Pull-Up selected
  [3] SYS_BOOT0_PULLUDENABLE rw — Pull-Up/Down enable for pad sys_boot0
    values as CONTROL_WKUP_PAD0_LLIA_WAKEREQIN_PAD1_LLIB_WAKEREQIN.LLIB_WAKEREQIN_PULLUDENABLE
  [2:0] SYS_BOOT0_MUXMODE rw — Functional multiplexing selection for pad sys_boot0
    6=SEL_GPIO1_WKOUT0 (Select gpio1_wkout0); 7=SEL_SAFE_MODE_WAKEUP17 (Select safe_mode_wakeup17); 0=SEL_SYS_BOOT0 (Select sys_boot0); 4=SEL_DRM_EMU15 (Select drm_emu15); 5=SEL_HW_WKDBG0 (Select hw_wkdbg0); 3=SEL_DRM_EMU2 (Select drm_emu2)
0x74 CONTROL_WKUP_PAD0_SYS_BOOT2_PAD1_SYS_BOOT3 reset 0x1000100 — Register control for Pads sys_boot2 and sys_boot3 Access conditions. Read: unrestricted, Write: unrestricted
  [24] SYS_BOOT3_INPUTENABLE rw — Input enable value for pad sys_boot3
    values as CONTROL_WKUP_PAD0_LLIA_WAKEREQIN_PAD1_LLIB_WAKEREQIN.LLIB_WAKEREQIN_INPUTENABLE
  [21] SYS_BOOT3_PWRDOWN rw — Power Down setting for pad sys_boot3
    values as CONTROL_WKUP_PAD0_LLIA_WAKEREQIN_PAD1_LLIB_WAKEREQIN.LLIB_WAKEREQIN_PWRDOWN
  [20] SYS_BOOT3_PULLTYPESELECT rw — Pull-Up/Down selection for pad sys_boot3
    0=Pull-Down selected; 1=Pull-Up selected
  [19] SYS_BOOT3_PULLUDENABLE rw — Pull-Up/Down enable for pad sys_boot3
    values as CONTROL_WKUP_PAD0_LLIA_WAKEREQIN_PAD1_LLIB_WAKEREQIN.LLIB_WAKEREQIN_PULLUDENABLE
  [18:16] SYS_BOOT3_MUXMODE rw — Functional multiplexing selection for pad sys_boot3
    0=SEL_SYS_BOOT3 (Select sys_boot3); 6=SEL_GPIO1_WKOUT3 (Select gpio1_wkout3); 4=SEL_DRM_EMU18 (Select drm_emu18); 7=SEL_SAFE_MODE_WAKEUP20 (Select safe_mode_wakeup20); 5=SEL_HW_WKDBG3 (Select hw_wkdbg3); 3=SEL_DRM_EMU5 (Select drm_emu5)
  [8] SYS_BOOT2_INPUTENABLE rw — Input enable value for pad sys_boot2
    values as CONTROL_WKUP_PAD0_LLIA_WAKEREQIN_PAD1_LLIB_WAKEREQIN.LLIB_WAKEREQIN_INPUTENABLE
  [5] SYS_BOOT2_PWRDOWN rw — Power Down setting for pad sys_boot2
    values as CONTROL_WKUP_PAD0_LLIA_WAKEREQIN_PAD1_LLIB_WAKEREQIN.LLIB_WAKEREQIN_PWRDOWN
  [4] SYS_BOOT2_PULLTYPESELECT rw — Pull-Up/Down selection for pad sys_boot2
    0=Pull-Down selected; 1=Pull-Up selected
  [3] SYS_BOOT2_PULLUDENABLE rw — Pull-Up/Down enable for pad sys_boot2
    values as CONTROL_WKUP_PAD0_LLIA_WAKEREQIN_PAD1_LLIB_WAKEREQIN.LLIB_WAKEREQIN_PULLUDENABLE
  [2:0] SYS_BOOT2_MUXMODE rw — Functional multiplexing selection for pad sys_boot2
    0=SEL_SYS_BOOT2 (Select sys_boot2); 6=SEL_GPIO1_WKOUT2 (Select gpio1_wkout2); 4=SEL_DRM_EMU17 (Select drm_emu17); 7=SEL_SAFE_MODE_WAKEUP19 (Select safe_mode_wakeup19); 5=SEL_HW_WKDBG2 (Select hw_wkdbg2); 3=SEL_DRM_EMU4 (Select drm_emu4)
0x78 CONTROL_WKUP_PAD0_SYS_BOOT4_PAD1_SYS_BOOT5 reset 0x1000100 — Register control for Pads sys_boot4 and sys_boot5 Access conditions. Read: unrestricted, Write: unrestricted
  [24] SYS_BOOT5_INPUTENABLE rw — Input enable value for pad sys_boot5
    values as CONTROL_WKUP_PAD0_LLIA_WAKEREQIN_PAD1_LLIB_WAKEREQIN.LLIB_WAKEREQIN_INPUTENABLE
  [21] SYS_BOOT5_PWRDOWN rw — Power Down setting for pad sys_boot5
    values as CONTROL_WKUP_PAD0_LLIA_WAKEREQIN_PAD1_LLIB_WAKEREQIN.LLIB_WAKEREQIN_PWRDOWN
  [20] SYS_BOOT5_PULLTYPESELECT rw — Pull-Up/Down selection for pad sys_boot5
    0=Pull-Down selected; 1=Pull-Up selected
  [19] SYS_BOOT5_PULLUDENABLE rw — Pull-Up/Down enable for pad sys_boot5
    values as CONTROL_WKUP_PAD0_LLIA_WAKEREQIN_PAD1_LLIB_WAKEREQIN.LLIB_WAKEREQIN_PULLUDENABLE
  [18:16] SYS_BOOT5_MUXMODE rw — Functional multiplexing selection for pad sys_boot5
    0=SEL_SYS_BOOT5 (Select sys_boot5); 1=SEL_SYS_AUX_MSECURE (Reserved); 6=SEL_GPIO1_WKOUT5 (Select gpio1_wkout5); 7=SEL_SAFE_MODE_WAKEUP22 (Select safe_mode_wakeup22); 5=SEL_HW_WKDBG8 (Select hw_wkdbg8)
  [8] SYS_BOOT4_INPUTENABLE rw — Input enable value for pad sys_boot4
    values as CONTROL_WKUP_PAD0_LLIA_WAKEREQIN_PAD1_LLIB_WAKEREQIN.LLIB_WAKEREQIN_INPUTENABLE
  [5] SYS_BOOT4_PWRDOWN rw — Power Down setting for pad sys_boot4
    values as CONTROL_WKUP_PAD0_LLIA_WAKEREQIN_PAD1_LLIB_WAKEREQIN.LLIB_WAKEREQIN_PWRDOWN
  [4] SYS_BOOT4_PULLTYPESELECT rw — Pull-Up/Down selection for pad sys_boot4
    0=Pull-Down selected; 1=Pull-Up selected
  [3] SYS_BOOT4_PULLUDENABLE rw — Pull-Up/Down enable for pad sys_boot4
    values as CONTROL_WKUP_PAD0_LLIA_WAKEREQIN_PAD1_LLIB_WAKEREQIN.LLIB_WAKEREQIN_PULLUDENABLE
  [2:0] SYS_BOOT4_MUXMODE rw — Functional multiplexing selection for pad sys_boot4
    0=SEL_SYS_BOOT4 (Select sys_boot4); 6=SEL_GPIO1_WKOUT4 (Select gpio1_wkout4); 4=SEL_DRM_EMU19 (Select drm_emu19); 7=SEL_SAFE_MODE_WAKEUP21 (Select safe_mode_wakeup21); 5=SEL_HW_WKDBG4 (Select hw_wkdbg4); 3=SEL_DRM_EMU6 (Select drm_emu6)
0x80 CONTROL_PADCONF_WAKEUPEVENT_0 ro — Access conditions. Read: unrestricted, Write: unrestricted
  [all] fields
    1=WakeUp (A wakeup event occurred); 0=No wakeup event occurred
  [31] C2C_DATA9_DUPLICATEWAKEUPEVENT — Wake-up event status latched in the IO for pad c2c_data9
  [30] C2C_DATA8_DUPLICATEWAKEUPEVENT — Wake-up event status latched in the IO for pad c2c_data8
  [n+22] C2C_DATAOUT{n}_DUPLICATEWAKEUPEVENT (n=0..7) — Wake-up event status latched in the IO for pad c2c_dataout{n}
  [n+14] C2C_DATAIN{n}_DUPLICATEWAKEUPEVENT (n=0..7) — Wake-up event status latched in the IO for pad c2c_datain{n}
  [13] C2C_CLKIN1_DUPLICATEWAKEUPEVENT — Wake-up event status latched in the IO for pad c2c_clkin1
  [12] C2C_CLKIN0_DUPLICATEWAKEUPEVENT — Wake-up event status latched in the IO for pad c2c_clkin0
  [11] C2C_CLKOUT1_DUPLICATEWAKEUPEVENT — Wake-up event status latched in the IO for pad c2c_clkout1
  [10] C2C_CLKOUT0_DUPLICATEWAKEUPEVENT — Wake-up event status latched in the IO for pad c2c_clkout0
  [n+2] EMMC_DATA{n}_DUPLICATEWAKEUPEVENT (n=0..7) — Wake-up event status latched in the IO for pad emmc_data{n}
  [1] EMMC_CMD_DUPLICATEWAKEUPEVENT — Wake-up event status latched in the IO for pad emmc_cmd
  [0] EMMC_CLK_DUPLICATEWAKEUPEVENT — Wake-up event status latched in the IO for pad emmc_clk
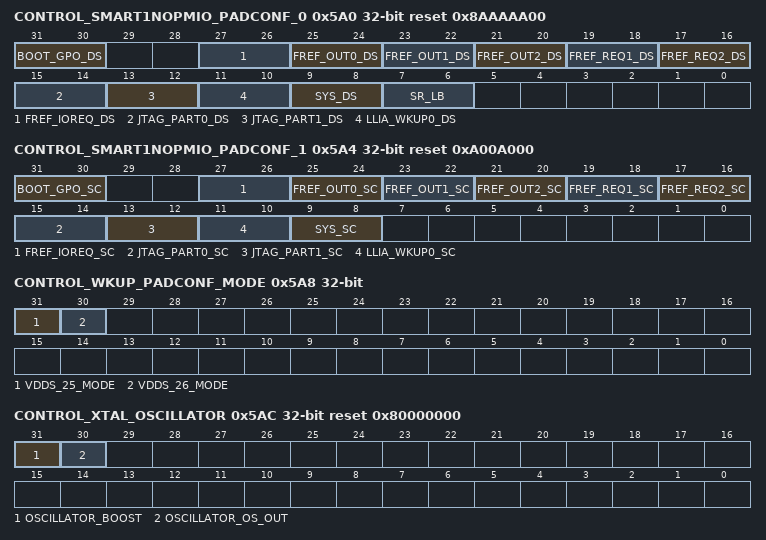
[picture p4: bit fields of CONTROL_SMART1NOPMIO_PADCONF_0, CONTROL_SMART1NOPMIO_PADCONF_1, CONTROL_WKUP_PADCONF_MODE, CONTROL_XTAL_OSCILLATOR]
0x5A0 CONTROL_SMART1NOPMIO_PADCONF_0 reset 0x8AAAAA00 — SMART1 NOPM IO control 0 Access conditions. Read: unrestricted, Write: unrestricted
  [31:30] BOOT_GPO_DS rw — drive stength for boot gpo ds
    0=ds0 (120 ohm); 1=ds1 (60 ohm); 3=ds3 (30 ohm); 2=ds2 (45 ohm)
  [27:26] FREF_IOREQ_DS rw — drive stength for fref ioreq ds
    values as BOOT_GPO_DS
  [25:24] FREF_OUT0_DS rw — drive stength for fref out0 ds
    values as BOOT_GPO_DS
  [23:22] FREF_OUT1_DS rw — drive stength for fref out1 ds
    values as BOOT_GPO_DS
  [21:20] FREF_OUT2_DS rw — drive stength for fref out2 ds
    values as BOOT_GPO_DS
  [19:18] FREF_REQ1_DS rw — drive stength for fref req1 ds
    values as BOOT_GPO_DS
  [17:16] FREF_REQ2_DS rw — drive stength for fref req2 ds
    values as BOOT_GPO_DS
  [15:14] JTAG_PART0_DS rw — drive stength for jtag part0 ds
    values as BOOT_GPO_DS
  [13:12] JTAG_PART1_DS rw — drive stength for jtag part1 ds
    values as BOOT_GPO_DS
  [11:10] LLIA_WKUP0_DS rw — drive stength for llia wakeup0 ds
    values as BOOT_GPO_DS
  [9:8] SYS_DS rw — drive stength for sys ds
    values as BOOT_GPO_DS
  [7:6] SR_LB rw — Control for internal pull-up resistors in both Fast and High-Speed modes for sr group of pads:In Fast-Speed mode: . In High-Speed mode: .
    0=FS_5-15pf (5-15pf); 1=FS_15-50pf (15-50pf); 3=FS_N_A (N/A); 2=FS_50-150pf (50-150pf); 0=HS_5-12pf (5-12pf); 1=HS_12-25pf (12-25pf); 3=HS_50-80pf (50-80pf); 2=HS_25-50pf (25-50pf)
0x5A4 CONTROL_SMART1NOPMIO_PADCONF_1 reset 0xA00A000 — SMART1 NOPM IO control 1 Access conditions. Read: unrestricted, Write: unrestricted
  [all] fields
    0=sc0 (slow); 1=sc1 (medium); 3=sc3 (not_applicable); 2=sc2 (fast)
  [31:30] BOOT_GPO_SC rw — slew rate control for boot gpo sc
  [27:26] FREF_IOREQ_SC rw — slew rate control for fref ioreq sc
  [25:24] FREF_OUT0_SC rw — slew rate control for fref out0 sc
  [23:22] FREF_OUT1_SC rw — slew rate control for fref out1 sc
  [21:20] FREF_OUT2_SC rw — slew rate control for fref out2 sc
  [19:18] FREF_REQ1_SC rw — slew rate control for fref req1 sc
  [17:16] FREF_REQ2_SC rw — slew rate control for fref req2 sc
  [15:14] JTAG_PART0_SC rw — slew rate control for jtag part0 sc
  [13:12] JTAG_PART1_SC rw — slew rate control for jtag part1 sc
  [11:10] LLIA_WKUP0_SC rw — slew rate control for llia wakeup0 sc
  [9:8] SYS_SC rw — slew rate control for sys sc
0x5A8 CONTROL_WKUP_PADCONF_MODE — PAD Conf Mode Access conditions. Read: unrestricted, Write: unrestricted
  [31] VDDS_25_MODE rw — PAD Voltage level control for vdds_25_mode
    0=1V8 (VDDS = 1.8V); 1=1V2 (VDDS = 1.2V)
  [30] VDDS_26_MODE rw — PAD Voltage level control for vdds_26_mode
    0=1V8 (VDDS = 1.8V); 1=1V2 (VDDS = 1.2V)
0x5AC CONTROL_XTAL_OSCILLATOR reset 0x80000000 — XTAL OSCILLATOR control Access conditions. Read: unrestricted, Write: unrestricted
  [31] OSCILLATOR_BOOST rw — Fast startup control
    0=Disable (Fast startup is disabled); 1=Enable (Fast startup is enabled)
  [30] OSCILLATOR_OS_OUT ro — Oscillator output
    1=Disable (BOOST is disabled); 0=Enable (low to high transition in BOOST mode)
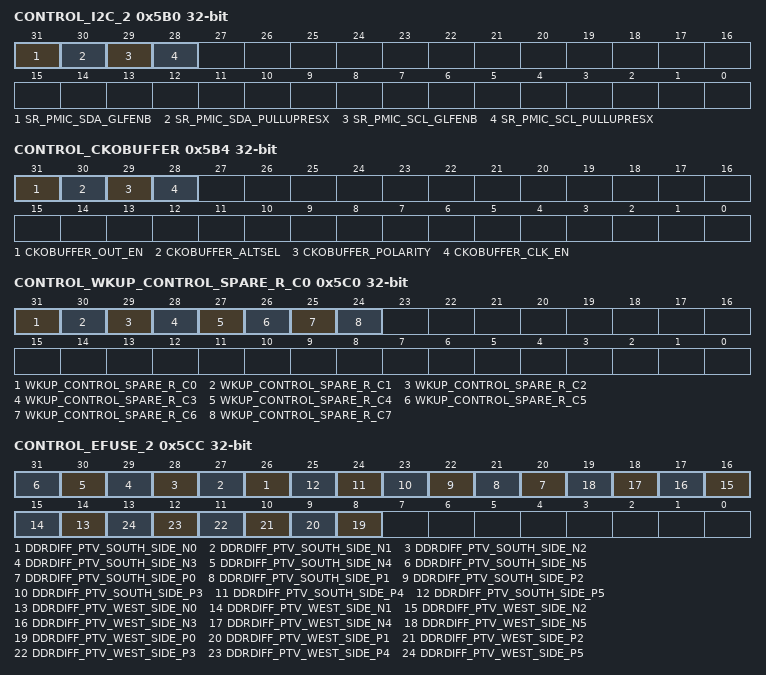
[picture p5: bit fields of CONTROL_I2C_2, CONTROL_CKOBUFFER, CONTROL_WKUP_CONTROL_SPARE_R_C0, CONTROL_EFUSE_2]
0x5B0 CONTROL_I2C_2 — I2C pads control 2 Access conditions. Read: unrestricted, Write: unrestricted
  [31] SR_PMIC_SDA_GLFENB rw — Active_high glitch free operation enable pin for pmic_sda receiver
    0=Disable pmic_sda glitch free operation; 1=Enable pmic_sda glitch free operation
  [30] SR_PMIC_SDA_PULLUPRESX rw — Active_low internal pull_up resistor enabled for pmic_sda
    0=Enable Internal Pull up resistor; 1=Disable Internal Pull up resisitor
  [29] SR_PMIC_SCL_GLFENB rw — Active_high glitch free operation enable pin for pmic_scl receiver
    0=Disable pmic_scl glitch free operation; 1=Enable pmic_scl glitch free operation
  [28] SR_PMIC_SCL_PULLUPRESX rw — Active_low internal pull_up resistor enabled for pmic_scl
    values as SR_PMIC_SDA_PULLUPRESX
0x5B4 CONTROL_CKOBUFFER — CKO buffer control Access conditions. Read: unrestricted, Write: unrestricted
  [31] CKOBUFFER_OUT_EN rw — Output buffer enable. 0x0: The output buffer is driving a clock signal 0x1: The output buffer (fref_xtal_clk pad) does not drive a clock signal. Its output value depends on the value of the CKOBUFFER_POLARITY bit.
  [30] CKOBUFFER_ALTSEL rw — Selects an alternative clock source. 0x0: The output buffer drives the same signal present on the fref_xtal_in pad 0x1: The output buffer drives an alternative clock. In this case 0 is present on the pad. There is no alternative clock.
  [29] CKOBUFFER_POLARITY rw — Defines the polarity of the clock-out buffer when the CKOBUFFER_OUT_EN bit is set to 0x0. 0x0: The output buffer is 0. 0x1: The output buffer is 1.
  [28] CKOBUFFER_CLK_EN rw — Output clock enable control. 0x0: The output clock is disabled. 0x1: The output clock is enabled.
0x5B8 CONTROL_WKUP_CONTROL_SPARE_RW rw — WKUP control spare RW Access conditions. Read: unrestricted, Write: unrestricted
  [31:0] WKUP_CONTROL_SPARE_RW — wkup control spare register bits RW
0x5BC CONTROL_WKUP_CONTROL_SPARE_R ro — WKUP control spare R Access conditions. Read: unrestricted, Write: unrestricted
  [31:0] WKUP_CONTROL_SPARE_R — wkup control spare register bits R
0x5C0 CONTROL_WKUP_CONTROL_SPARE_R_C0 access not given — WKUP control spare RC Access conditions. Read: unrestricted, Write: unrestricted
  [31-n] WKUP_CONTROL_SPARE_R_C{n} (n=0..7) — wkup control spare register bits RC (access RW W1toClr)
0x5CC CONTROL_EFUSE_2 — EFUSE compensation 2. Since reset value is exported, at the time of control module generation, reset value is not known. Using 0 as default Access conditions. Read: unrestricted, Write: unrestricted
  [n+26] DDRDIFF_PTV_SOUTH_SIDE_N{n} rw (n=0..5) — control_ddrdiff_ptv_south_side_n{n} Note that reset is exported. Its value is = pi_ddrdiff_ptv_south_side_n{n}
  [n+20] DDRDIFF_PTV_SOUTH_SIDE_P{n} rw (n=0..5) — control_ddrdiff_ptv_south_side_p{n} Note that reset is exported. Its value is = pi_ddrdiff_ptv_south_side_p{n}
  [n+14] DDRDIFF_PTV_WEST_SIDE_N{n} rw (n=0..5) — control_ddrdiff_ptv_west_side_n{n} Note that reset is exported. Its value is = pi_ddrdiff_ptv_west_side_n{n}
  [n+8] DDRDIFF_PTV_WEST_SIDE_P{n} rw (n=0..5) — control_ddrdiff_ptv_west_side_p{n} Note that reset is exported. Its value is = pi_ddrdiff_ptv_west_side_p{n}
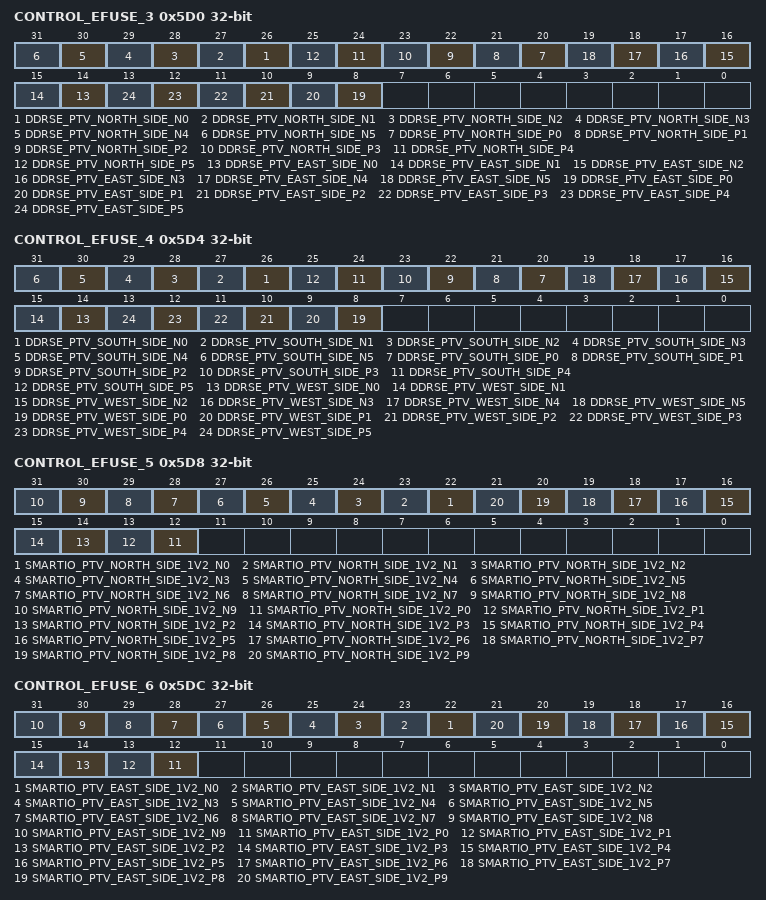
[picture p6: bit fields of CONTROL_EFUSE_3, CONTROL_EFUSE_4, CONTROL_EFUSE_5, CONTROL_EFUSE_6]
0x5D0 CONTROL_EFUSE_3 — EFUSE compensation 3. Since reset value is exported, at the time of control module generation, reset value is not known. Using 0 as default Access conditions. Read: unrestricted, Write: unrestricted
  [n+26] DDRSE_PTV_NORTH_SIDE_N{n} rw (n=0..5) — control_ddrse_ptv_north_side_n{n} Note that reset is exported. Its value is = pi_ddrse_ptv_north_side_n{n}
  [n+20] DDRSE_PTV_NORTH_SIDE_P{n} rw (n=0..5) — control_ddrse_ptv_north_side_p{n} Note that reset is exported. Its value is = pi_ddrse_ptv_north_side_p{n}
  [n+14] DDRSE_PTV_EAST_SIDE_N{n} rw (n=0..5) — control_ddrse_ptv_east_side_n{n} Note that reset is exported. Its value is = pi_ddrse_ptv_east_side_n{n}
  [n+8] DDRSE_PTV_EAST_SIDE_P{n} rw (n=0..5) — control_ddrse_ptv_east_side_p{n} Note that reset is exported. Its value is = pi_ddrse_ptv_east_side_p{n}
0x5D4 CONTROL_EFUSE_4 — EFUSE compensation 4. Since reset value is exported, at the time of control module generation, reset value is not known. Using 0 as default Access conditions. Read: unrestricted, Write: unrestricted
  [n+26] DDRSE_PTV_SOUTH_SIDE_N{n} rw (n=0..5) — control_ddrse_ptv_south_side_n{n} Note that reset is exported. Its value is = pi_ddrse_ptv_south_side_n{n}
  [n+20] DDRSE_PTV_SOUTH_SIDE_P{n} rw (n=0..5) — control_ddrse_ptv_south_side_p{n} Note that reset is exported. Its value is = pi_ddrse_ptv_south_side_p{n}
  [n+14] DDRSE_PTV_WEST_SIDE_N{n} rw (n=0..5) — control_ddrse_ptv_west_side_n{n} Note that reset is exported. Its value is = pi_ddrse_ptv_west_side_n{n}
  [n+8] DDRSE_PTV_WEST_SIDE_P{n} rw (n=0..5) — control_ddrse_ptv_west_side_p{n} Note that reset is exported. Its value is = pi_ddrse_ptv_west_side_p{n}
0x5D8 CONTROL_EFUSE_5 — EFUSE compensation 5. Since reset value is exported, at the time of control module generation, reset value is not known. Using 0 as default Access conditions. Read: unrestricted, Write: unrestricted
  [n+22] SMARTIO_PTV_NORTH_SIDE_1V2_N{n} rw (n=0..9) — control_smartio_ptv_north_side_1v2_n{n} Note that reset is exported. Its value is = pi_smartio_ptv_north_side_1v2_n{n}
  [n+12] SMARTIO_PTV_NORTH_SIDE_1V2_P{n} rw (n=0..9) — control_smartio_ptv_north_side_1v2_p{n} Note that reset is exported. Its value is = pi_smartio_ptv_north_side_1v2_p{n}
0x5DC CONTROL_EFUSE_6 — EFUSE compensation 6. Since reset value is exported, at the time of control module generation, reset value is not known. Using 0 as default Access conditions. Read: unrestricted, Write: unrestricted
  [n+22] SMARTIO_PTV_EAST_SIDE_1V2_N{n} rw (n=0..9) — control_smartio_ptv_east_side_1v2_n{n} Note that reset is exported. Its value is = pi_smartio_ptv_east_side_1v2_n{n}
  [n+12] SMARTIO_PTV_EAST_SIDE_1V2_P{n} rw (n=0..9) — control_smartio_ptv_east_side_1v2_p{n} Note that reset is exported. Its value is = pi_smartio_ptv_east_side_1v2_p{n}
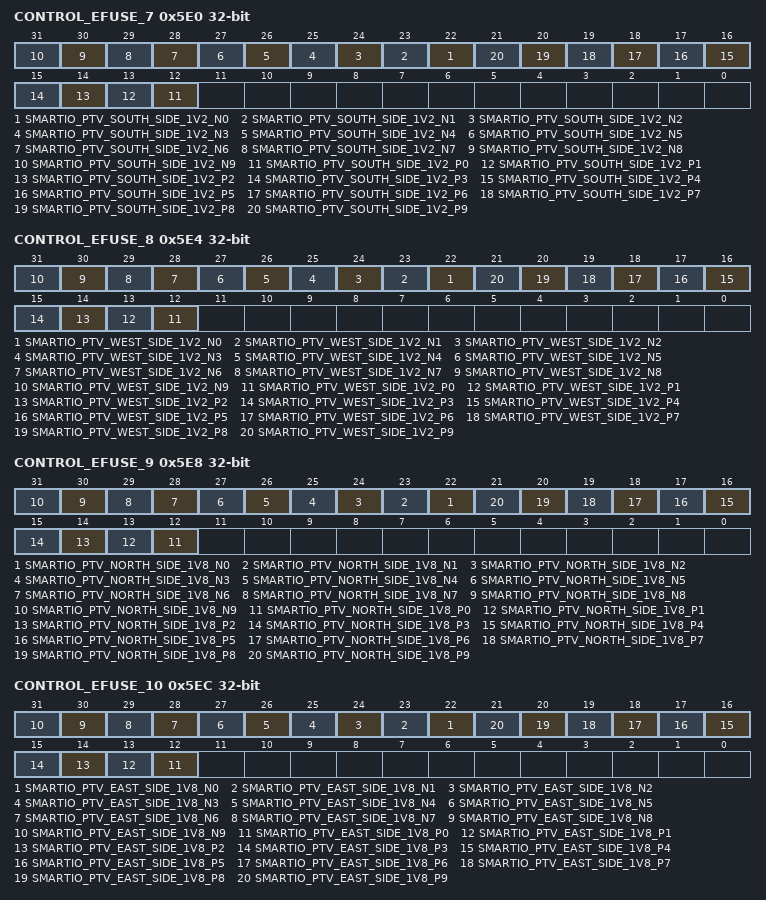
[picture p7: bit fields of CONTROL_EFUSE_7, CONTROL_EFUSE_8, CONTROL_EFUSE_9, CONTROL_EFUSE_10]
0x5E0 CONTROL_EFUSE_7 — EFUSE compensation 7. Since reset value is exported, at the time of control module generation, reset value is not known. Using 0 as default Access conditions. Read: unrestricted, Write: unrestricted
  [n+22] SMARTIO_PTV_SOUTH_SIDE_1V2_N{n} rw (n=0..9) — control_smartio_ptv_south_side_1v2_n{n} Note that reset is exported. Its value is = pi_smartio_ptv_south_side_1v2_n{n}
  [n+12] SMARTIO_PTV_SOUTH_SIDE_1V2_P{n} rw (n=0..9) — control_smartio_ptv_south_side_1v2_p{n} Note that reset is exported. Its value is = pi_smartio_ptv_south_side_1v2_p{n}
0x5E4 CONTROL_EFUSE_8 — EFUSE compensation 8. Since reset value is exported, at the time of control module generation, reset value is not known. Using 0 as default Access conditions. Read: unrestricted, Write: unrestricted
  [n+22] SMARTIO_PTV_WEST_SIDE_1V2_N{n} rw (n=0..9) — control_smartio_ptv_west_side_1v2_n{n} Note that reset is exported. Its value is = pi_smartio_ptv_west_side_1v2_n{n}
  [n+12] SMARTIO_PTV_WEST_SIDE_1V2_P{n} rw (n=0..9) — control_smartio_ptv_west_side_1v2_p{n} Note that reset is exported. Its value is = pi_smartio_ptv_west_side_1v2_p{n}
0x5E8 CONTROL_EFUSE_9 — EFUSE compensation 9. Since reset value is exported, at the time of control module generation, reset value is not known. Using 0 as default Access conditions. Read: unrestricted, Write: unrestricted
  [n+22] SMARTIO_PTV_NORTH_SIDE_1V8_N{n} rw (n=0..9) — control_smartio_ptv_north_side_1v8_n{n} Note that reset is exported. Its value is = pi_smartio_ptv_north_side_1v8_n{n}
  [n+12] SMARTIO_PTV_NORTH_SIDE_1V8_P{n} rw (n=0..9) — control_smartio_ptv_north_side_1v8_p{n} Note that reset is exported. Its value is = pi_smartio_ptv_north_side_1v8_p{n}
0x5EC CONTROL_EFUSE_10 — EFUSE compensation 10. Since reset value is exported, at the time of control module generation, reset value is not known. Using 0 as default Access conditions. Read: unrestricted, Write: unrestricted
  [n+22] SMARTIO_PTV_EAST_SIDE_1V8_N{n} rw (n=0..9) — control_smartio_ptv_east_side_1v8_n{n} Note that reset is exported. Its value is = pi_smartio_ptv_east_side_1v8_n{n}
  [n+12] SMARTIO_PTV_EAST_SIDE_1V8_P{n} rw (n=0..9) — control_smartio_ptv_east_side_1v8_p{n} Note that reset is exported. Its value is = pi_smartio_ptv_east_side_1v8_p{n}
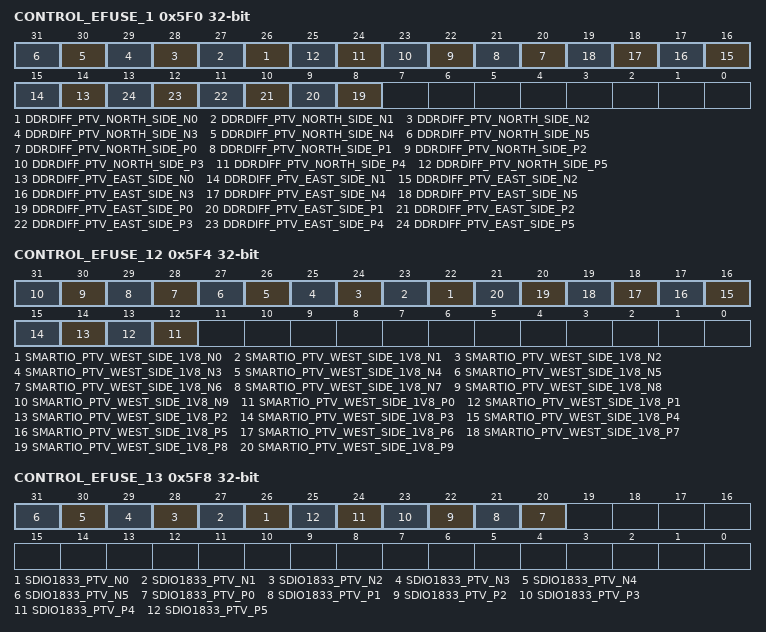
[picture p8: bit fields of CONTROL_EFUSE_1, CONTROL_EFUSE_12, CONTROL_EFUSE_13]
0x5F0 CONTROL_EFUSE_1 — EFUSE compensation 1. Since reset value is exported, at the time of control module generation, reset value is not known. Using 0 as default Access conditions. Read: unrestricted, Write: unrestricted
  [n+26] DDRDIFF_PTV_NORTH_SIDE_N{n} rw (n=0..5) — control_ddrdiff_ptv_north_side_n{n} Note that reset is exported. Its value is = pi_ddrdiff_ptv_north_side_n{n}
  [n+20] DDRDIFF_PTV_NORTH_SIDE_P{n} rw (n=0..5) — control_ddrdiff_ptv_north_side_p{n} Note that reset is exported. Its value is = pi_ddrdiff_ptv_north_side_p{n}
  [n+14] DDRDIFF_PTV_EAST_SIDE_N{n} rw (n=0..5) — control_ddrdiff_ptv_east_side_n{n} Note that reset is exported. Its value is = pi_ddrdiff_ptv_east_side_n{n}
  [n+8] DDRDIFF_PTV_EAST_SIDE_P{n} rw (n=0..5) — control_ddrdiff_ptv_east_side_p{n} Note that reset is exported. Its value is = pi_ddrdiff_ptv_east_side_p{n}
0x5F4 CONTROL_EFUSE_12 — EFUSE compensation 12. Since reset value is exported, at the time of control module generation, reset value is not known. Using 0 as default Access conditions. Read: unrestricted, Write: unrestricted
  [n+22] SMARTIO_PTV_WEST_SIDE_1V8_N{n} rw (n=0..9) — control_smartio_ptv_west_side_1v8_n{n} Note that reset is exported. Its value is = pi_smartio_ptv_west_side_1v8_n{n}
  [n+12] SMARTIO_PTV_WEST_SIDE_1V8_P{n} rw (n=0..9) — control_smartio_ptv_west_side_1v8_p{n} Note that reset is exported. Its value is = pi_smartio_ptv_west_side_1v8_p{n}
0x5F8 CONTROL_EFUSE_13 — EFUSE compensation 13. Since reset value is exported, at the time of control module generation, reset value is not known. Using 0 as default Access conditions. Read: unrestricted, Write: unrestricted
  [n+26] SDIO1833_PTV_N{n} rw (n=0..5) — control_sdio1833_ptv_n{n} Note that reset is exported. Its value is = pi_sdio1833_ptv_n{n}
  [n+20] SDIO1833_PTV_P{n} rw (n=0..5) — control_sdio1833_ptv_p{n} Note that reset is exported. Its value is = pi_sdio1833_ptv_p{n}
